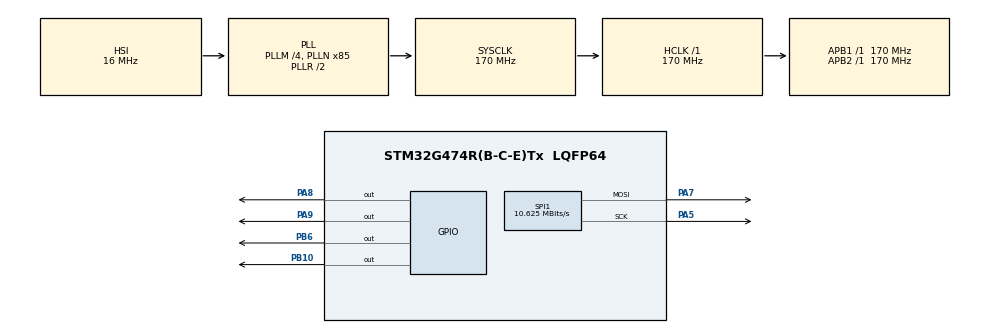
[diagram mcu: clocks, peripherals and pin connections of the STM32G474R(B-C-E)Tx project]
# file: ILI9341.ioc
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Mcu.Family=STM32G4
Mcu.Name=STM32G474R(B-C-E)Tx
Mcu.Package=LQFP64
NVIC.PriorityGroup=NVIC_PRIORITYGROUP_4
PA13.Mode=Serial_Wire
PA13.Signal=SYS_JTMS-SWDIO
PA14.Mode=Serial_Wire
PA14.Signal=SYS_JTCK-SWCLK
PA5.Mode=TX_Only_Simplex_Unidirect_Master
PA5.Signal=SPI1_SCK
PA7.Mode=TX_Only_Simplex_Unidirect_Master
PA7.Signal=SPI1_MOSI
PA8.PinState=GPIO_PIN_SET
PA8.Signal=GPIO_Output
PA9.Signal=GPIO_Output
PB10.PinState=GPIO_PIN_SET
PB10.Signal=GPIO_Output
PB6.PinState=GPIO_PIN_SET
PB6.Signal=GPIO_Output
PF0-OSC_IN.Mode=HSE-External-Oscillator
PF0-OSC_IN.Signal=RCC_OSC_IN
PF1-OSC_OUT.Mode=HSE-External-Oscillator
PF1-OSC_OUT.Signal=RCC_OSC_OUT
ProjectManager.HeapSize=0x200
ProjectManager.StackSize=0x400
ProjectManager.TargetToolchain=STM32CubeIDE
RCC.ADC12Freq_Value=170000000
RCC.ADC345Freq_Value=170000000
RCC.AHBFreq_Value=170000000
RCC.APB1Freq_Value=170000000
RCC.APB1TimFreq_Value=170000000
RCC.APB2Freq_Value=170000000
RCC.APB2TimFreq_Value=170000000
RCC.CortexFreq_Value=170000000
RCC.EXTERNAL_CLOCK_VALUE=12288000
RCC.HCLKFreq_Value=170000000
RCC.HSI48_VALUE=48000000
RCC.HSI_VALUE=16000000
RCC.LSE_VALUE=32768
RCC.PLLM=RCC_PLLM_DIV4
RCC.PLLN=85
RCC.SYSCLKFreq_VALUE=170000000
RCC.SYSCLKSource=RCC_SYSCLKSOURCE_PLLCLK
RCC.USBFreq_Value=170000000
RCC.VCOOutputFreq_Value=340000000
SPI1.BaudRatePrescaler=SPI_BAUDRATEPRESCALER_16
SPI1.CalculateBaudRate=10.625 MBits/s
SPI1.DataSize=SPI_DATASIZE_8BIT
SPI1.Direction=SPI_DIRECTION_2LINES
SPI1.Mode=SPI_MODE_MASTER
SPI1.VirtualType=VM_MASTER
VP_SYS_VS_DBSignals.Mode=DisableDeadBatterySignals
board=custom

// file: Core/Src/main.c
/* USER CODE BEGIN Header */
/**
  ******************************************************************************
  * @file           : main.c
  * @brief          : ILI9341 RGB test
  ******************************************************************************
  */
/* USER CODE END Header */

#include "main.h"
#include "spi.h"
#include "gpio.h"

/* USER CODE BEGIN Includes */
#include "ili9341.h"
#include "ili9341_image.h"
/* USER CODE END Includes */

void SystemClock_Config(void);

int main(void)
{

  /* MCU Configuration--------------------------------------------------------*/

  HAL_Init();

  SystemClock_Config();

  MX_GPIO_Init();
  MX_SPI1_Init();

  /* USER CODE BEGIN 2 */
  if (ILI9341_Init() != HAL_OK)
  {
    Error_Handler();
  }

  if (ILI9341_DrawRGB565Image(g_ili9341_image_rgb565,
                              ILI9341_IMAGE_DATA_SIZE,
                              ILI9341_IMAGE_WIDTH,
                              ILI9341_IMAGE_HEIGHT) != HAL_OK)
  {
    Error_Handler();
  }
  /* USER CODE END 2 */

  /* Infinite loop */
  while (1)
  {

    /* USER CODE BEGIN 3 */
    HAL_Delay(1000U);
  }
  /* USER CODE END 3 */
}

void SystemClock_Config(void)
{
  RCC_OscInitTypeDef RCC_OscInitStruct = {0};
  RCC_ClkInitTypeDef RCC_ClkInitStruct = {0};

  HAL_PWREx_ControlVoltageScaling(PWR_REGULATOR_VOLTAGE_SCALE1_BOOST);

  RCC_OscInitStruct.OscillatorType = RCC_OSCILLATORTYPE_HSI;
  RCC_OscInitStruct.HSIState = RCC_HSI_ON;
  RCC_OscInitStruct.HSICalibrationValue = RCC_HSICALIBRATION_DEFAULT;
  RCC_OscInitStruct.PLL.PLLState = RCC_PLL_ON;
  RCC_OscInitStruct.PLL.PLLSource = RCC_PLLSOURCE_HSI;
  RCC_OscInitStruct.PLL.PLLM = RCC_PLLM_DIV4;
  RCC_OscInitStruct.PLL.PLLN = 85;
  RCC_OscInitStruct.PLL.PLLP = RCC_PLLP_DIV2;
  RCC_OscInitStruct.PLL.PLLQ = RCC_PLLQ_DIV2;
  RCC_OscInitStruct.PLL.PLLR = RCC_PLLR_DIV2;
  if (HAL_RCC_OscConfig(&RCC_OscInitStruct) != HAL_OK)
  {
    Error_Handler();
  }

  RCC_ClkInitStruct.ClockType = RCC_CLOCKTYPE_HCLK |
                                RCC_CLOCKTYPE_SYSCLK |
                                RCC_CLOCKTYPE_PCLK1 |
                                RCC_CLOCKTYPE_PCLK2;
  RCC_ClkInitStruct.SYSCLKSource = RCC_SYSCLKSOURCE_PLLCLK;
  RCC_ClkInitStruct.AHBCLKDivider = RCC_SYSCLK_DIV1;
  RCC_ClkInitStruct.APB1CLKDivider = RCC_HCLK_DIV1;
  RCC_ClkInitStruct.APB2CLKDivider = RCC_HCLK_DIV1;

  if (HAL_RCC_ClockConfig(&RCC_ClkInitStruct, FLASH_LATENCY_4) != HAL_OK)
  {
    Error_Handler();
  }
}

void Error_Handler(void)
{
  __disable_irq();
  while (1)
  {
  }
}

#ifdef USE_FULL_ASSERT
/**
  * @brief  Reports the name of the source file and the source line number
  *         where the assert_param error has occurred.
  * @param  file: pointer to the source file name
  * @param  line: source line number
  * @retval None
  */
void assert_failed(uint8_t *file, uint32_t line)
{
  /* USER CODE BEGIN 6 */
  (void)file;
  (void)line;
  /* USER CODE END 6 */
}
#endif /* USE_FULL_ASSERT */
